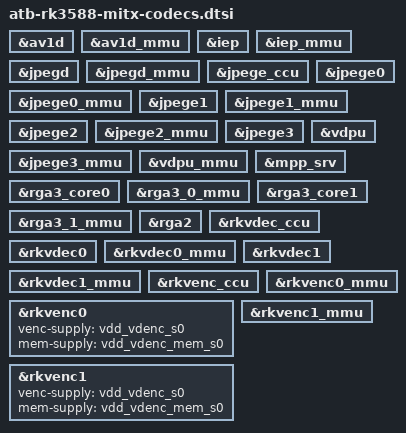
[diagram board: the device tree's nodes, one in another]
&av1d {
	status = "okay";
};

&av1d_mmu {
	status = "okay";
};

&iep {
	status = "okay";
};

&iep_mmu {
	status = "okay";
};

&jpegd {
	status = "okay";
};

&jpegd_mmu {
	status = "okay";
};

&jpege_ccu {
	status = "okay";
};

&jpege0 {
	status = "okay";
};

&jpege0_mmu {
	status = "okay";
};

&jpege1 {
	status = "okay";
};

&jpege1_mmu {
	status = "okay";
};

&jpege2 {
	status = "okay";
};

&jpege2_mmu {
	status = "okay";
};

&jpege3 {
	status = "okay";
};

&jpege3_mmu {
	status = "okay";
};

&vdpu {
	status = "okay";
};

&vdpu_mmu {
	status = "okay";
};

&mpp_srv {
	status = "okay";
};

&rga3_core0 {
	status = "okay";
};

&rga3_0_mmu {
	status = "okay";
};

&rga3_core1 {
	status = "okay";
};

&rga3_1_mmu {
	status = "okay";
};

&rga2 {
	status = "okay";
};

&rkvdec_ccu {
	status = "okay";
};

&rkvdec0 {
	status = "okay";
};

&rkvdec0_mmu {
	status = "okay";
};

&rkvdec1 {
	status = "okay";
};

&rkvdec1_mmu {
	status = "okay";
};

&rkvenc_ccu {
	status = "okay";
};

&rkvenc0 {
	venc-supply = <&vdd_vdenc_s0>;
	mem-supply = <&vdd_vdenc_mem_s0>;
	status = "okay";
};

&rkvenc0_mmu {
	status = "okay";
};

&rkvenc1 {
	venc-supply = <&vdd_vdenc_s0>;
	mem-supply = <&vdd_vdenc_mem_s0>;
	status = "okay";
};

&rkvenc1_mmu {
	status = "okay";
};
